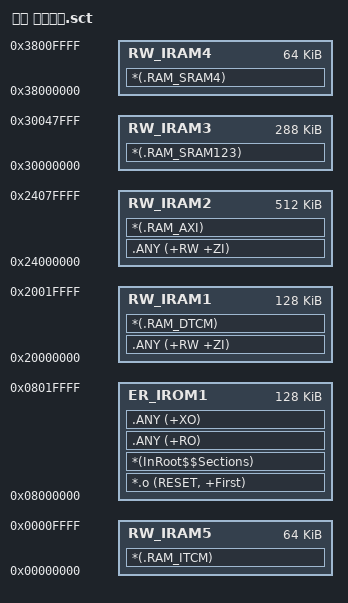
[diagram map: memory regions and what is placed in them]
LR_IROM1 0x08000000 0x00020000  
{    ; load region size_region
  ER_IROM1 0x08000000 0x00020000  
  {  ; load address = execution address
   *.o (RESET, +First)
   *(InRoot$$Sections)
   .ANY (+RO)
   .ANY (+XO)
  }

   ; RW data - 128KB DTCM
 RW_IRAM1 0x20000000 0x00020000 
 { 
 .ANY (+RW +ZI)
 *(.RAM_DTCM)
 }
 
 ; RW data - 512KB AXI SRAM
 RW_IRAM2 0x24000000 0x00080000 
 { 
   .ANY (+RW +ZI)
 *(.RAM_AXI) 
 }
 
 ; RW data - 128KB SRAM1(0x30000000) + 128KB SRAM2(0x3002 0000) + 32KB SRAM3(0x30040000)
 RW_IRAM3 0x30000000 0x00048000 
 { 
 *(.RAM_SRAM123)
 }
 
 ; RW data - 64KB SRAM4(0x38000000)
 RW_IRAM4 0x38000000 0x00010000
 { 
 *(.RAM_SRAM4)
 }
  ; RW data - 64KB ITCM(0x000000)
 RW_IRAM5 0x0000000 0x00010000 
 { 
 *(.RAM_ITCM)
 }
}

;LR_ROM1 0x90000000 0x00800000  
;{
;  ER_ROM1 0x90000000 0x00800000 
;  {  ; load address = execution address
;   .ANY (+RO)
;  }
;}
